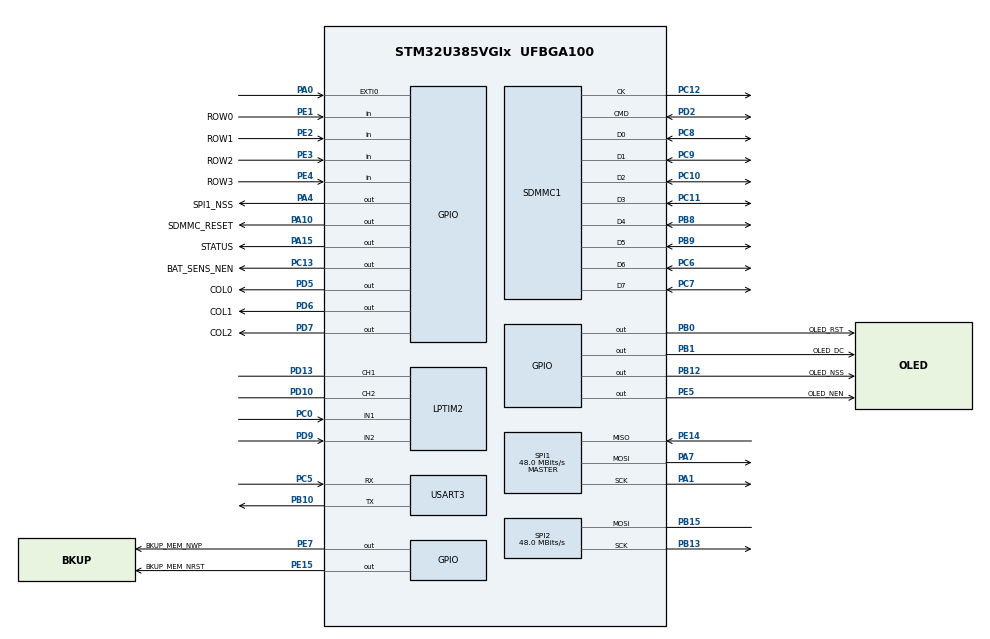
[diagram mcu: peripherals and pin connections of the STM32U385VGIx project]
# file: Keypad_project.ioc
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AES.Header=__NULL
AES.KeySize=CRYP_KEYSIZE_256B
CORTEX_M33_NS.userName=CORTEX_M33
HASH.Algorithm=HASH_ALGOSELECTION_SHA512
HASH.HASHMAC=No
Mcu.Family=STM32U3
Mcu.Name=STM32U385VGIx
Mcu.Package=UFBGA100
NVIC.EXTI0_IRQn=true\:0\:0\:false\:false\:true\:true\:true\:true
NVIC.PriorityGroup=NVIC_PRIORITYGROUP_4
NVIC.TIM1_UP_IRQn=true\:0\:0\:false\:false\:true\:true\:true\:true
PA0.GPIO_ModeDefaultEXTI=GPIO_MODE_IT_RISING_FALLING
PA0.Signal=GPXTI0
PA1.Mode=Full_Duplex_Master
PA1.Signal=SPI1_SCK
PA10.GPIO_Label=SDMMC_RESET
PA10.Signal=GPIO_Output
PA13\ (JTMS/SWDIO).Mode=Trace_Asynchronous_SW
PA13\ (JTMS/SWDIO).Signal=DEBUG_JTMS-SWDIO
PA14\ (JTCK/SWCLK).Mode=Trace_Asynchronous_SW
PA14\ (JTCK/SWCLK).Signal=DEBUG_JTCK-SWCLK
PA15\ (JTDI).GPIO_Label=STATUS
PA15\ (JTDI).GPIO_ModeDefaultOutputPP=GPIO_MODE_OUTPUT_OD
PA15\ (JTDI).GPIO_PuPd=GPIO_PULLUP
PA15\ (JTDI).Signal=GPIO_Output
PA4.GPIO_Label=SPI1_NSS
PA4.Signal=GPIO_Output
PA7.Mode=Full_Duplex_Master
PA7.Signal=SPI1_MOSI
PB0.GPIO_Label=OLED_RST
PB0.Signal=GPIO_Output
PB1.GPIO_Label=OLED_DC
PB1.Signal=GPIO_Output
PB10.Mode=Asynchronous
PB10.Signal=USART3_TX
PB12.GPIO_Label=OLED_NSS
PB12.Signal=GPIO_Output
PB13.Mode=Simplex_Bidirectional_Master
PB13.Signal=SPI2_SCK
PB15.Mode=Simplex_Bidirectional_Master
PB15.Signal=SPI2_MOSI
PB3\ (JTDO/TRACESWO).Mode=Trace_Asynchronous_SW
PB3\ (JTDO/TRACESWO).Signal=DEBUG_JTDO-SWO
PB8.Mode=mmc_8_bits_Wide_bus
PB8.Signal=SDMMC1_D4
PB9.Mode=mmc_8_bits_Wide_bus
PB9.Signal=SDMMC1_D5
PC0.Mode=Encoder_mode_occur1
PC0.Signal=LPTIM2_IN1
PC10.Mode=mmc_8_bits_Wide_bus
PC10.Signal=SDMMC1_D2
PC11.Mode=mmc_8_bits_Wide_bus
PC11.Signal=SDMMC1_D3
PC12.Mode=mmc_8_bits_Wide_bus
PC12.Signal=SDMMC1_CK
PC13.GPIO_Label=BAT_SENS_NEN
PC13.Signal=GPIO_Output
PC14-OSC32_IN\ (PC14).Mode=LSE-External-Oscillator-for-RTC
PC14-OSC32_IN\ (PC14).Signal=RCC_OSC32_IN
PC15-OSC32_OUT\ (PC15).Mode=LSE-External-Oscillator-for-RTC
PC15-OSC32_OUT\ (PC15).Signal=RCC_OSC32_OUT
PC5.Mode=Asynchronous
PC5.Signal=USART3_RX
PC6.Mode=mmc_8_bits_Wide_bus
PC6.Signal=SDMMC1_D6
PC7.Mode=mmc_8_bits_Wide_bus
PC7.Signal=SDMMC1_D7
PC8.Mode=mmc_8_bits_Wide_bus
PC8.Signal=SDMMC1_D0
PC9.Mode=mmc_8_bits_Wide_bus
PC9.Signal=SDMMC1_D1
PD10.Signal=S_LPTIM2_CH2
PD13.Signal=S_LPTIM2_CH1
PD2.Mode=mmc_8_bits_Wide_bus
PD2.Signal=SDMMC1_CMD
PD5.GPIO_Label=COL0
PD5.Signal=GPIO_Output
PD6.GPIO_Label=COL1
PD6.Signal=GPIO_Output
PD7.GPIO_Label=COL2
PD7.Signal=GPIO_Output
PD9.Mode=Encoder_mode_occur1
PD9.Signal=LPTIM2_IN2
PE1.GPIO_Label=ROW0
PE1.Signal=GPIO_Input
PE14.Mode=Full_Duplex_Master
PE14.Signal=SPI1_MISO
PE15.GPIO_Label=BKUP_MEM_NRST
PE15.Signal=GPIO_Output
PE2.GPIO_Label=ROW1
PE2.Signal=GPIO_Input
PE3.GPIO_Label=ROW2
PE3.Signal=GPIO_Input
PE4.GPIO_Label=ROW3
PE4.Signal=GPIO_Input
PE5.GPIO_Label=OLED_NEN
PE5.Signal=GPIO_Output
PE7.GPIO_Label=BKUP_MEM_NWP
PE7.Signal=GPIO_Output
PH0-OSC_IN\ (PH0).Mode=HSE-External-Oscillator
PH0-OSC_IN\ (PH0).Signal=RCC_OSC_IN
PH1-OSC_OUT\ (PH1).Mode=HSE-External-Oscillator
PH1-OSC_OUT\ (PH1).Signal=RCC_OSC_OUT
ProjectManager.HeapSize=0x1000
ProjectManager.StackSize=0x2000
ProjectManager.TargetToolchain=STM32CubeIDE
RCC.ADCFreq_Value=96000000
RCC.AHBFreq_Value=96000000
RCC.APB1Freq_Value=96000000
RCC.APB1TimFreq_Value=96000000
RCC.APB2Freq_Value=96000000
RCC.APB2TimFreq_Value=96000000
RCC.APB3Freq_Value=96000000
RCC.CortexFreq_Value=12000000
RCC.HCLKFreq_Value=96000000
RCC.HSE_VALUE=25000000
RCC.HSI48_VALUE=48000000
RCC.HSI_VALUE=16000000
RCC.LSIDIV_VALUE=32000
RCC.MSISDIV=RCC_MSI_DIV1
RCC.RTCClockSelection=RCC_RTCCLKSOURCE_LSE
RCC.SYSCLKFreq_VALUE=96000000
RCC.USBFreq_Value=48000000
RCC.USB_DIV=RCC_USB1CLKSOURCE_ICLK_DIV2
SH.S_LPTIM2_CH1.0=LPTIM2_CH1,InputIO_CH1
SH.S_LPTIM2_CH2.0=LPTIM2_CH2,InputIO_CH2
SPI1.CalculateBaudRate=48.0 MBits/s
SPI1.DataSize=SPI_DATASIZE_8BIT
SPI1.Direction=SPI_DIRECTION_2LINES
SPI1.Mode=SPI_MODE_MASTER
SPI1.VirtualType=VM_MASTER
SPI2.CalculateBaudRate=48.0 MBits/s
SPI2.Direction=SPI_DIRECTION_1LINE
SPI2.Mode=SPI_MODE_MASTER
SPI2.VirtualType=VM_MASTER
TIM1.AutoReloadPreload=TIM_AUTORELOAD_PRELOAD_ENABLE
TIM1.PeriodNoDither=16000
USART3.VirtualMode-Asynchronous=VM_ASYNC
VP_AES_VS_AES.Mode=AES_Activate
VP_CORTEX_M33_NS_VS_Hclk.Mode=Hclk_Mode
VP_CRC_VS_CRC.Mode=CRC_Activate
VP_HASH_VS_HASH.Mode=HASH_Activate
VP_LPTIM2_VS_CH1.Mode=Channel_1_Active
VP_LPTIM2_VS_CH2.Mode=Channel_2_Active
VP_MEMORYMAP_VS_MEMORYMAP.Mode=CurAppReg
VP_PWR_VS_DBSignals.Mode=DisableDeadBatterySignals
VP_PWR_VS_LPOM.Mode=PowerOptimisation
VP_PWR_VS_SECSignals.Mode=Security/Privilege
VP_RNG_VS_RNG.Mode=RNG_Activate
VP_RTC_VS_RTC_Activate.Mode=RTC_Enabled
VP_RTC_VS_RTC_Calendar.Mode=RTC_Calendar
VP_TIM1_VS_ClockSourceINT.Mode=Internal
board=custom

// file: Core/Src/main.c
/* USER CODE BEGIN Header */
/**
  ******************************************************************************
  * @file           : main.c
  * @brief          : Main program body
  ******************************************************************************
  * @attention
  *
  * Copyright (c) 2026 STMicroelectronics.
  * All rights reserved.
  *
  * This software is licensed under terms that can be found in the LICENSE file
  * in the root directory of this software component.
  * If no LICENSE file comes with this software, it is provided AS-IS.
  *
  ******************************************************************************
  */
/* USER CODE END Header */
#include "main.h"

/* USER CODE BEGIN Includes */
#include "PAL.h"
#include "cachel1_armv7.h"
/* USER CODE END Includes */

CRYP_HandleTypeDef hcryp;
__ALIGN_BEGIN static const uint32_t pKeyAES[8] __ALIGN_END = {
                            0x00000000,0x00000000,0x00000000,0x00000000,0x00000000,0x00000000,0x00000000,0x00000000};

CRC_HandleTypeDef hcrc;

HASH_HandleTypeDef hhash;

LPTIM_HandleTypeDef hlptim2;

RNG_HandleTypeDef hrng;

RTC_HandleTypeDef hrtc;

MMC_HandleTypeDef hmmc1;

SPI_HandleTypeDef hspi1;
SPI_HandleTypeDef hspi2;

TIM_HandleTypeDef htim1;

UART_HandleTypeDef huart3;

void SystemClock_Config(void);
static void MX_GPIO_Init(void);
static void MX_AES_Init(void);
static void MX_CRC_Init(void);
static void MX_HASH_Init(void);
static void MX_LPTIM2_Init(void);
static void MX_SDMMC1_MMC_Init(void);
static void MX_SPI1_Init(void);
static void MX_SPI2_Init(void);
static void MX_USART3_UART_Init(void);
static void MX_RTC_Init(void);
static void MX_RNG_Init(void);
static void MX_TIM1_Init(void);

/* USER CODE BEGIN 0 */
void HAL_GPIO_EXTI_Rising_Callback(uint16_t pin) {
	rotary_button_handler(1);
}
void HAL_GPIO_EXTI_Faling_Callback(uint16_t pin) {
	rotary_button_handler(0);
}
/* USER CODE END 0 */

int main(void)
{

  /* MCU Configuration--------------------------------------------------------*/

  /* Reset of all peripherals, Initializes the Flash interface and the Systick. */
  HAL_Init();

  /* Configure the system clock */
  SystemClock_Config();

  /* USER CODE BEGIN SysInit */
  // TODO: sdmmc is disabled!!!!!!!
  /* USER CODE END SysInit */

  /* Initialize all configured peripherals */
  MX_GPIO_Init();
  MX_AES_Init();
  MX_CRC_Init();
  MX_HASH_Init();
  MX_LPTIM2_Init();
  MX_SDMMC1_MMC_Init();
  MX_SPI1_Init();
  MX_SPI2_Init();
  MX_USART3_UART_Init();
  MX_RTC_Init();
  MX_RNG_Init();
  MX_TIM1_Init();
  /* USER CODE BEGIN 2 */

//  SCB_DisableDCache();
//  SCB_DisableICache();

//  MX_USB_PCD_Init();
//
//  HAL_PCDEx_PMAConfig(&hpcd_USB_DRD_FS, 0x00, PCD_SNG_BUF, 0x20);
//  HAL_PCDEx_PMAConfig(&hpcd_USB_DRD_FS, 0x80, PCD_SNG_BUF, 0x60);
//  _ux_dcd_stm32_initialize((ULONG)NULL, (ULONG)&hpcd_USB_DRD_FS);
//
//  HAL_PCD_Start(&hpcd_USB_DRD_FS); // start USB

  /* USER CODE END 2 */

  /* Infinite loop */
  /* USER CODE BEGIN WHILE */
  HAL_NVIC_EnableIRQ(EXTI0_IRQn);
  HAL_TIM_Base_Start_IT(&htim1);
  keypad_main();
    /* USER CODE END WHILE */

    /* USER CODE BEGIN 3 */
  for(;;) {
	//ux_device_stack_tasks_run();
  }
  /* USER CODE END 3 */
}

void SystemClock_Config(void)
{
  RCC_OscInitTypeDef RCC_OscInitStruct = {0};
  RCC_ClkInitTypeDef RCC_ClkInitStruct = {0};

  /** Enable Epod Booster
  */
  if (HAL_RCCEx_EpodBoosterClkConfig(RCC_EPODBOOSTER_SOURCE_MSIS, RCC_EPODBOOSTER_DIV1) != HAL_OK)
  {
    Error_Handler();
  }
  if (HAL_PWREx_EnableEpodBooster() != HAL_OK)
  {
    Error_Handler();
  }

  /** Configure the main internal regulator output voltage
  */
  if (HAL_PWREx_ControlVoltageScaling(PWR_REGULATOR_VOLTAGE_SCALE1) != HAL_OK)
  {
    Error_Handler();
  }

  /** Set Flash latency before increasing MSIS
  */
  __HAL_FLASH_SET_LATENCY(FLASH_LATENCY_2);

  /** Configure LSE Drive Capability
  */
  HAL_PWR_EnableBkUpAccess();
  __HAL_RCC_LSEDRIVE_CONFIG(RCC_LSEDRIVE_LOW);

  /** Initializes the CPU, AHB and APB buses clocks
  */
  RCC_OscInitStruct.OscillatorType = RCC_OSCILLATORTYPE_HSI48|RCC_OSCILLATORTYPE_LSE
                              |RCC_OSCILLATORTYPE_MSIS;
  RCC_OscInitStruct.HSI48State = RCC_HSI48_ON;
  RCC_OscInitStruct.LSEState = RCC_LSE_ON_RTC_ONLY;
  RCC_OscInitStruct.MSISState = RCC_MSI_ON;
  RCC_OscInitStruct.MSISSource = RCC_MSI_RC0;
  RCC_OscInitStruct.MSISDiv = RCC_MSI_DIV1;
  if (HAL_RCC_OscConfig(&RCC_OscInitStruct) != HAL_OK)
  {
    Error_Handler();
  }

  /** Initializes the CPU, AHB and APB buses clocks
  */
  RCC_ClkInitStruct.ClockType = RCC_CLOCKTYPE_HCLK|RCC_CLOCKTYPE_SYSCLK
                              |RCC_CLOCKTYPE_PCLK1|RCC_CLOCKTYPE_PCLK2
                              |RCC_CLOCKTYPE_PCLK3;
  RCC_ClkInitStruct.SYSCLKSource = RCC_SYSCLKSOURCE_MSIS;
  RCC_ClkInitStruct.AHBCLKDivider = RCC_SYSCLK_DIV1;
  RCC_ClkInitStruct.APB1CLKDivider = RCC_HCLK_DIV1;
  RCC_ClkInitStruct.APB2CLKDivider = RCC_HCLK_DIV1;
  RCC_ClkInitStruct.APB3CLKDivider = RCC_HCLK_DIV1;

  if (HAL_RCC_ClockConfig(&RCC_ClkInitStruct, FLASH_LATENCY_2) != HAL_OK)
  {
    Error_Handler();
  }
}

static void MX_AES_Init(void)
{

  hcryp.Instance = AES;
  hcryp.Init.DataType = CRYP_NO_SWAP;
  hcryp.Init.KeySize = CRYP_KEYSIZE_256B;
  hcryp.Init.pKey = (uint32_t *)pKeyAES;
  hcryp.Init.Algorithm = CRYP_AES_ECB;
  hcryp.Init.DataWidthUnit = CRYP_DATAWIDTHUNIT_WORD;
  hcryp.Init.HeaderWidthUnit = CRYP_HEADERWIDTHUNIT_WORD;
  hcryp.Init.KeyIVConfigSkip = CRYP_KEYIVCONFIG_ALWAYS;
  hcryp.Init.KeyMode = CRYP_KEYMODE_NORMAL;
  if (HAL_CRYP_Init(&hcryp) != HAL_OK)
  {
    Error_Handler();
  }

}

static void MX_CRC_Init(void)
{

  hcrc.Instance = CRC;
  hcrc.Init.DefaultPolynomialUse = DEFAULT_POLYNOMIAL_ENABLE;
  hcrc.Init.DefaultInitValueUse = DEFAULT_INIT_VALUE_ENABLE;
  hcrc.Init.InputDataInversionMode = CRC_INPUTDATA_INVERSION_NONE;
  hcrc.Init.OutputDataInversionMode = CRC_OUTPUTDATA_INVERSION_DISABLE;
  hcrc.InputDataFormat = CRC_INPUTDATA_FORMAT_BYTES;
  if (HAL_CRC_Init(&hcrc) != HAL_OK)
  {
    Error_Handler();
  }

}

static void MX_HASH_Init(void)
{

  hhash.Instance = HASH;
  hhash.Init.DataType = HASH_NO_SWAP;
  hhash.Init.Algorithm = HASH_ALGOSELECTION_SHA512;
  if (HAL_HASH_Init(&hhash) != HAL_OK)
  {
    Error_Handler();
  }

}

static void MX_LPTIM2_Init(void)
{

  LPTIM_IC_ConfigTypeDef sConfig = {0};

  hlptim2.Instance = LPTIM2;
  hlptim2.Init.Clock.Source = LPTIM_CLOCKSOURCE_APBCLOCK_LPOSC;
  hlptim2.Init.Clock.Prescaler = LPTIM_PRESCALER_DIV1;
  hlptim2.Init.UltraLowPowerClock.Polarity = LPTIM_CLOCKPOLARITY_RISING;
  hlptim2.Init.UltraLowPowerClock.SampleTime = LPTIM_CLOCKSAMPLETIME_DIRECTTRANSITION;
  hlptim2.Init.Trigger.Source = LPTIM_TRIGSOURCE_SOFTWARE;
  hlptim2.Init.Period = 65535;
  hlptim2.Init.UpdateMode = LPTIM_UPDATE_IMMEDIATE;
  hlptim2.Init.CounterSource = LPTIM_COUNTERSOURCE_EXTERNAL;
  hlptim2.Init.Input1Source = LPTIM_INPUT1SOURCE_GPIO;
  hlptim2.Init.RepetitionCounter = 0;
  if (HAL_LPTIM_Init(&hlptim2) != HAL_OK)
  {
    Error_Handler();
  }
  sConfig.ICInputSource = LPTIM_IC1SOURCE_GPIO;
  sConfig.ICPrescaler = LPTIM_ICPSC_DIV1;
  sConfig.ICPolarity = LPTIM_ICPOLARITY_RISING;
  sConfig.ICFilter = LPTIM_ICFLT_CLOCK_DIV1;
  if (HAL_LPTIM_IC_ConfigChannel(&hlptim2, &sConfig, LPTIM_CHANNEL_1) != HAL_OK)
  {
    Error_Handler();
  }
  sConfig.ICInputSource = LPTIM_IC2SOURCE_GPIO;
  if (HAL_LPTIM_IC_ConfigChannel(&hlptim2, &sConfig, LPTIM_CHANNEL_2) != HAL_OK)
  {
    Error_Handler();
  }

}

static void MX_RNG_Init(void)
{

  hrng.Instance = RNG;
  hrng.Init.ClockErrorDetection = RNG_CED_ENABLE;
  if (HAL_RNG_Init(&hrng) != HAL_OK)
  {
    Error_Handler();
  }

}

static void MX_RTC_Init(void)
{

  RTC_PrivilegeStateTypeDef privilegeState = {0};
  RTC_TimeTypeDef sTime = {0};
  RTC_DateTypeDef sDate = {0};

  /** Initialize RTC Only
  */
  hrtc.Instance = RTC;
  hrtc.Init.HourFormat = RTC_HOURFORMAT_24;
  hrtc.Init.AsynchPrediv = 127;
  hrtc.Init.SynchPrediv = 255;
  hrtc.Init.OutPut = RTC_OUTPUT_DISABLE;
  hrtc.Init.OutPutRemap = RTC_OUTPUT_REMAP_NONE;
  hrtc.Init.OutPutPolarity = RTC_OUTPUT_POLARITY_HIGH;
  hrtc.Init.OutPutType = RTC_OUTPUT_TYPE_OPENDRAIN;
  hrtc.Init.OutPutPullUp = RTC_OUTPUT_PULLUP_NONE;
  hrtc.Init.BinMode = RTC_BINARY_NONE;
  if (HAL_RTC_Init(&hrtc) != HAL_OK)
  {
    Error_Handler();
  }
  privilegeState.rtcPrivilegeFull = RTC_PRIVILEGE_FULL_NO;
  privilegeState.backupRegisterPrivZone = RTC_PRIVILEGE_BKUP_ZONE_NONE;
  privilegeState.backupRegisterStartZone2 = RTC_BKP_DR0;
  privilegeState.backupRegisterStartZone3 = RTC_BKP_DR0;
  if (HAL_RTCEx_PrivilegeModeSet(&hrtc, &privilegeState) != HAL_OK)
  {
    Error_Handler();
  }

  /** Initialize RTC and set the Time and Date
  */
  sTime.Hours = 0x0;
  sTime.Minutes = 0x0;
  sTime.Seconds = 0x0;
  sTime.DayLightSaving = RTC_DAYLIGHTSAVING_NONE;
  sTime.StoreOperation = RTC_STOREOPERATION_RESET;
  if (HAL_RTC_SetTime(&hrtc, &sTime, RTC_FORMAT_BCD) != HAL_OK)
  {
    Error_Handler();
  }
  sDate.WeekDay = RTC_WEEKDAY_MONDAY;
  sDate.Month = RTC_MONTH_JANUARY;
  sDate.Date = 0x1;
  sDate.Year = 0x0;

  if (HAL_RTC_SetDate(&hrtc, &sDate, RTC_FORMAT_BCD) != HAL_OK)
  {
    Error_Handler();
  }

}

static void MX_SDMMC1_MMC_Init(void)
{

  /* USER CODE BEGIN SDMMC1_Init 0 */
	return;	// TODO: connect EMMC chip
  /* USER CODE END SDMMC1_Init 0 */

  hmmc1.Instance = SDMMC1;
  hmmc1.Init.ClockEdge = SDMMC_CLOCK_EDGE_RISING;
  hmmc1.Init.ClockPowerSave = SDMMC_CLOCK_POWER_SAVE_DISABLE;
  hmmc1.Init.BusWide = SDMMC_BUS_WIDE_8B;
  hmmc1.Init.HardwareFlowControl = SDMMC_HARDWARE_FLOW_CONTROL_DISABLE;
  hmmc1.Init.ClockDiv = 0;
  if (HAL_MMC_Init(&hmmc1) != HAL_OK)
  {
    Error_Handler();
  }

}

static void MX_SPI1_Init(void)
{

  SPI_AutonomousModeConfTypeDef HAL_SPI_AutonomousMode_Cfg_Struct = {0};

  /* SPI1 parameter configuration*/
  hspi1.Instance = SPI1;
  hspi1.Init.Mode = SPI_MODE_MASTER;
  hspi1.Init.Direction = SPI_DIRECTION_2LINES;
  hspi1.Init.DataSize = SPI_DATASIZE_8BIT;
  hspi1.Init.CLKPolarity = SPI_POLARITY_LOW;
  hspi1.Init.CLKPhase = SPI_PHASE_1EDGE;
  hspi1.Init.NSS = SPI_NSS_SOFT;
  hspi1.Init.BaudRatePrescaler = SPI_BAUDRATEPRESCALER_2;
  hspi1.Init.FirstBit = SPI_FIRSTBIT_MSB;
  hspi1.Init.TIMode = SPI_TIMODE_DISABLE;
  hspi1.Init.CRCCalculation = SPI_CRCCALCULATION_DISABLE;
  hspi1.Init.CRCPolynomial = 0x7;
  hspi1.Init.NSSPMode = SPI_NSS_PULSE_ENABLE;
  hspi1.Init.NSSPolarity = SPI_NSS_POLARITY_LOW;
  hspi1.Init.FifoThreshold = SPI_FIFO_THRESHOLD_01DATA;
  hspi1.Init.MasterSSIdleness = SPI_MASTER_SS_IDLENESS_00CYCLE;
  hspi1.Init.MasterInterDataIdleness = SPI_MASTER_INTERDATA_IDLENESS_00CYCLE;
  hspi1.Init.MasterReceiverAutoSusp = SPI_MASTER_RX_AUTOSUSP_DISABLE;
  hspi1.Init.MasterKeepIOState = SPI_MASTER_KEEP_IO_STATE_DISABLE;
  hspi1.Init.IOSwap = SPI_IO_SWAP_DISABLE;
  hspi1.Init.ReadyMasterManagement = SPI_RDY_MASTER_MANAGEMENT_INTERNALLY;
  hspi1.Init.ReadyPolarity = SPI_RDY_POLARITY_HIGH;
  if (HAL_SPI_Init(&hspi1) != HAL_OK)
  {
    Error_Handler();
  }
  HAL_SPI_AutonomousMode_Cfg_Struct.TriggerState = SPI_AUTO_MODE_DISABLE;
  HAL_SPI_AutonomousMode_Cfg_Struct.TriggerSelection = SPI_GRP1_GPDMA_CH0_TCF_TRG;
  HAL_SPI_AutonomousMode_Cfg_Struct.TriggerPolarity = SPI_TRIG_POLARITY_RISING;
  if (HAL_SPIEx_SetConfigAutonomousMode(&hspi1, &HAL_SPI_AutonomousMode_Cfg_Struct) != HAL_OK)
  {
    Error_Handler();
  }

}

static void MX_SPI2_Init(void)
{

  SPI_AutonomousModeConfTypeDef HAL_SPI_AutonomousMode_Cfg_Struct = {0};

  /* SPI2 parameter configuration*/
  hspi2.Instance = SPI2;
  hspi2.Init.Mode = SPI_MODE_MASTER;
  hspi2.Init.Direction = SPI_DIRECTION_1LINE;
  hspi2.Init.DataSize = SPI_DATASIZE_4BIT;
  hspi2.Init.CLKPolarity = SPI_POLARITY_LOW;
  hspi2.Init.CLKPhase = SPI_PHASE_1EDGE;
  hspi2.Init.NSS = SPI_NSS_SOFT;
  hspi2.Init.BaudRatePrescaler = SPI_BAUDRATEPRESCALER_2;
  hspi2.Init.FirstBit = SPI_FIRSTBIT_MSB;
  hspi2.Init.TIMode = SPI_TIMODE_DISABLE;
  hspi2.Init.CRCCalculation = SPI_CRCCALCULATION_DISABLE;
  hspi2.Init.CRCPolynomial = 0x7;
  hspi2.Init.NSSPMode = SPI_NSS_PULSE_ENABLE;
  hspi2.Init.NSSPolarity = SPI_NSS_POLARITY_LOW;
  hspi2.Init.FifoThreshold = SPI_FIFO_THRESHOLD_01DATA;
  hspi2.Init.MasterSSIdleness = SPI_MASTER_SS_IDLENESS_00CYCLE;
  hspi2.Init.MasterInterDataIdleness = SPI_MASTER_INTERDATA_IDLENESS_00CYCLE;
  hspi2.Init.MasterReceiverAutoSusp = SPI_MASTER_RX_AUTOSUSP_DISABLE;
  hspi2.Init.MasterKeepIOState = SPI_MASTER_KEEP_IO_STATE_DISABLE;
  hspi2.Init.IOSwap = SPI_IO_SWAP_DISABLE;
  hspi2.Init.ReadyMasterManagement = SPI_RDY_MASTER_MANAGEMENT_INTERNALLY;
  hspi2.Init.ReadyPolarity = SPI_RDY_POLARITY_HIGH;
  if (HAL_SPI_Init(&hspi2) != HAL_OK)
  {
    Error_Handler();
  }
  HAL_SPI_AutonomousMode_Cfg_Struct.TriggerState = SPI_AUTO_MODE_DISABLE;
  HAL_SPI_AutonomousMode_Cfg_Struct.TriggerSelection = SPI_GRP1_GPDMA_CH0_TCF_TRG;
  HAL_SPI_AutonomousMode_Cfg_Struct.TriggerPolarity = SPI_TRIG_POLARITY_RISING;
  if (HAL_SPIEx_SetConfigAutonomousMode(&hspi2, &HAL_SPI_AutonomousMode_Cfg_Struct) != HAL_OK)
  {
    Error_Handler();
  }

}

static void MX_TIM1_Init(void)
{

  TIM_ClockConfigTypeDef sClockSourceConfig = {0};
  TIM_MasterConfigTypeDef sMasterConfig = {0};

  htim1.Instance = TIM1;
  htim1.Init.Prescaler = 0;
  htim1.Init.CounterMode = TIM_COUNTERMODE_UP;
  htim1.Init.Period = 16000;
  htim1.Init.ClockDivision = TIM_CLOCKDIVISION_DIV1;
  htim1.Init.RepetitionCounter = 0;
  htim1.Init.AutoReloadPreload = TIM_AUTORELOAD_PRELOAD_ENABLE;
  if (HAL_TIM_Base_Init(&htim1) != HAL_OK)
  {
    Error_Handler();
  }
  sClockSourceConfig.ClockSource = TIM_CLOCKSOURCE_INTERNAL;
  if (HAL_TIM_ConfigClockSource(&htim1, &sClockSourceConfig) != HAL_OK)
  {
    Error_Handler();
  }
  sMasterConfig.MasterOutputTrigger = TIM_TRGO_RESET;
  sMasterConfig.MasterOutputTrigger2 = TIM_TRGO2_RESET;
  sMasterConfig.MasterSlaveMode = TIM_MASTERSLAVEMODE_DISABLE;
  if (HAL_TIMEx_MasterConfigSynchronization(&htim1, &sMasterConfig) != HAL_OK)
  {
    Error_Handler();
  }

}

static void MX_USART3_UART_Init(void)
{

  huart3.Instance = USART3;
  huart3.Init.BaudRate = 115200;
  huart3.Init.WordLength = UART_WORDLENGTH_8B;
  huart3.Init.StopBits = UART_STOPBITS_1;
  huart3.Init.Parity = UART_PARITY_NONE;
  huart3.Init.Mode = UART_MODE_TX_RX;
  huart3.Init.HwFlowCtl = UART_HWCONTROL_NONE;
  huart3.Init.OverSampling = UART_OVERSAMPLING_16;
  huart3.Init.OneBitSampling = UART_ONE_BIT_SAMPLE_DISABLE;
  huart3.Init.ClockPrescaler = UART_PRESCALER_DIV1;
  huart3.AdvancedInit.AdvFeatureInit = UART_ADVFEATURE_NO_INIT;
  if (HAL_UART_Init(&huart3) != HAL_OK)
  {
    Error_Handler();
  }
  if (HAL_UARTEx_SetTxFifoThreshold(&huart3, UART_TXFIFO_THRESHOLD_1_8) != HAL_OK)
  {
    Error_Handler();
  }
  if (HAL_UARTEx_SetRxFifoThreshold(&huart3, UART_RXFIFO_THRESHOLD_1_8) != HAL_OK)
  {
    Error_Handler();
  }
  if (HAL_UARTEx_DisableFifoMode(&huart3) != HAL_OK)
  {
    Error_Handler();
  }

}

static void MX_GPIO_Init(void)
{
  GPIO_InitTypeDef GPIO_InitStruct = {0};

  /* GPIO Ports Clock Enable */
  __HAL_RCC_GPIOE_CLK_ENABLE();
  __HAL_RCC_GPIOB_CLK_ENABLE();
  __HAL_RCC_GPIOD_CLK_ENABLE();
  __HAL_RCC_GPIOA_CLK_ENABLE();
  __HAL_RCC_GPIOC_CLK_ENABLE();

  /*Configure GPIO pin Output Level */
  HAL_GPIO_WritePin(GPIOD, COL2_Pin|COL0_Pin|COL1_Pin, GPIO_PIN_RESET);

  /*Configure GPIO pin Output Level */
  HAL_GPIO_WritePin(GPIOA, STATUS_Pin|SDMMC_RESET_Pin|SPI1_NSS_Pin, GPIO_PIN_RESET);

  /*Configure GPIO pin Output Level */
  HAL_GPIO_WritePin(BAT_SENS_NEN_GPIO_Port, BAT_SENS_NEN_Pin, GPIO_PIN_RESET);

  /*Configure GPIO pin Output Level */
  HAL_GPIO_WritePin(GPIOE, OLED_NEN_Pin|BKUP_MEM_NWP_Pin|BKUP_MEM_NRST_Pin, GPIO_PIN_RESET);

  /*Configure GPIO pin Output Level */
  HAL_GPIO_WritePin(GPIOB, OLED_NSS_Pin|OLED_RST_Pin|OLED_DC_Pin, GPIO_PIN_RESET);

  /*Configure GPIO pins : ROW2_Pin ROW0_Pin ROW3_Pin ROW1_Pin */
  GPIO_InitStruct.Pin = ROW2_Pin|ROW0_Pin|ROW3_Pin|ROW1_Pin;
  GPIO_InitStruct.Mode = GPIO_MODE_INPUT;
  GPIO_InitStruct.Pull = GPIO_NOPULL;
  HAL_GPIO_Init(GPIOE, &GPIO_InitStruct);

  /*Configure GPIO pins : COL2_Pin COL0_Pin COL1_Pin */
  GPIO_InitStruct.Pin = COL2_Pin|COL0_Pin|COL1_Pin;
  GPIO_InitStruct.Mode = GPIO_MODE_OUTPUT_PP;
  GPIO_InitStruct.Pull = GPIO_NOPULL;
  GPIO_InitStruct.Speed = GPIO_SPEED_FREQ_LOW;
  HAL_GPIO_Init(GPIOD, &GPIO_InitStruct);

  /*Configure GPIO pin : PB3 */
  GPIO_InitStruct.Pin = GPIO_PIN_3;
  GPIO_InitStruct.Mode = GPIO_MODE_AF_PP;
  GPIO_InitStruct.Pull = GPIO_NOPULL;
  GPIO_InitStruct.Speed = GPIO_SPEED_FREQ_LOW;
  GPIO_InitStruct.Alternate = GPIO_AF0_TRACE;
  HAL_GPIO_Init(GPIOB, &GPIO_InitStruct);

  /*Configure GPIO pin : STATUS_Pin */
  GPIO_InitStruct.Pin = STATUS_Pin;
  GPIO_InitStruct.Mode = GPIO_MODE_OUTPUT_OD;
  GPIO_InitStruct.Pull = GPIO_PULLUP;
  GPIO_InitStruct.Speed = GPIO_SPEED_FREQ_LOW;
  HAL_GPIO_Init(STATUS_GPIO_Port, &GPIO_InitStruct);

  /*Configure GPIO pin : PA13 */
  GPIO_InitStruct.Pin = GPIO_PIN_13;
  GPIO_InitStruct.Mode = GPIO_MODE_AF_PP;
  GPIO_InitStruct.Pull = GPIO_PULLUP;
  GPIO_InitStruct.Speed = GPIO_SPEED_FREQ_LOW;
  GPIO_InitStruct.Alternate = GPIO_AF0_TRACE;
  HAL_GPIO_Init(GPIOA, &GPIO_InitStruct);

  /*Configure GPIO pin : BAT_SENS_NEN_Pin */
  GPIO_InitStruct.Pin = BAT_SENS_NEN_Pin;
  GPIO_InitStruct.Mode = GPIO_MODE_OUTPUT_PP;
  GPIO_InitStruct.Pull = GPIO_NOPULL;
  GPIO_InitStruct.Speed = GPIO_SPEED_FREQ_LOW;
  HAL_GPIO_Init(BAT_SENS_NEN_GPIO_Port, &GPIO_InitStruct);

  /*Configure GPIO pins : OLED_NEN_Pin BKUP_MEM_NWP_Pin BKUP_MEM_NRST_Pin */
  GPIO_InitStruct.Pin = OLED_NEN_Pin|BKUP_MEM_NWP_Pin|BKUP_MEM_NRST_Pin;
  GPIO_InitStruct.Mode = GPIO_MODE_OUTPUT_PP;
  GPIO_InitStruct.Pull = GPIO_NOPULL;
  GPIO_InitStruct.Speed = GPIO_SPEED_FREQ_LOW;
  HAL_GPIO_Init(GPIOE, &GPIO_InitStruct);

  /*Configure GPIO pins : SDMMC_RESET_Pin SPI1_NSS_Pin */
  GPIO_InitStruct.Pin = SDMMC_RESET_Pin|SPI1_NSS_Pin;
  GPIO_InitStruct.Mode = GPIO_MODE_OUTPUT_PP;
  GPIO_InitStruct.Pull = GPIO_NOPULL;
  GPIO_InitStruct.Speed = GPIO_SPEED_FREQ_LOW;
  HAL_GPIO_Init(GPIOA, &GPIO_InitStruct);

  /*Configure GPIO pin : PA0 */
  GPIO_InitStruct.Pin = GPIO_PIN_0;
  GPIO_InitStruct.Mode = GPIO_MODE_IT_RISING_FALLING;
  GPIO_InitStruct.Pull = GPIO_NOPULL;
  HAL_GPIO_Init(GPIOA, &GPIO_InitStruct);

  /*Configure GPIO pins : OLED_NSS_Pin OLED_RST_Pin OLED_DC_Pin */
  GPIO_InitStruct.Pin = OLED_NSS_Pin|OLED_RST_Pin|OLED_DC_Pin;
  GPIO_InitStruct.Mode = GPIO_MODE_OUTPUT_PP;
  GPIO_InitStruct.Pull = GPIO_NOPULL;
  GPIO_InitStruct.Speed = GPIO_SPEED_FREQ_LOW;
  HAL_GPIO_Init(GPIOB, &GPIO_InitStruct);

  /* EXTI interrupt init*/
  HAL_NVIC_SetPriority(EXTI0_IRQn, 0, 0);
  HAL_NVIC_EnableIRQ(EXTI0_IRQn);

}

void Error_Handler(void)
{
  __disable_irq();
  while (1)
  {
  }
}
